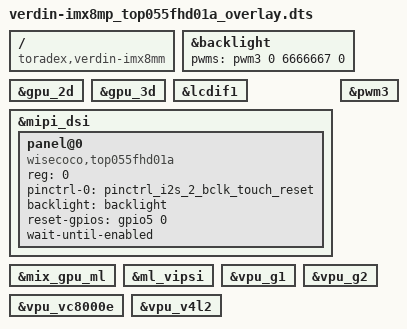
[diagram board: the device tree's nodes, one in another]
// Verdin DSI to HDMI Adapter orderable at Toradex.

/dts-v1/;
/plugin/;

#include <dt-bindings/gpio/gpio.h>

/ {
	compatible = "toradex,verdin-imx8mm";
};

&backlight {
	pwms = <&pwm3 0 6666667 0>;
	status = "okay";
};

&gpu_2d {
	status = "okay";
};

&gpu_3d {
	status = "okay";
};

&lcdif1 {
	status = "okay";
};

&mipi_dsi {
	#address-cells = <1>;
	#size-cells = <0>;
	status = "okay";

	panel@0 {
		compatible = "wisecoco,top055fhd01a";
		reg = <0>;
		pinctrl-names = "default";
		pinctrl-0 = <&pinctrl_i2s_2_bclk_touch_reset>;
		backlight = <&backlight>;
		reset-gpios = <&gpio5 0 GPIO_ACTIVE_HIGH>;
		wait-until-enabled;
		status = "okay";
	};
};

&mix_gpu_ml {
	status = "okay";
};

&ml_vipsi {
	status = "okay";
};

&pwm3 {
	status = "okay";
};

&vpu_g1 {
	status = "okay";
};

&vpu_g2 {
	status = "okay";
};

&vpu_vc8000e {
	status = "okay";
};

&vpu_v4l2 {
	status = "okay";
};
